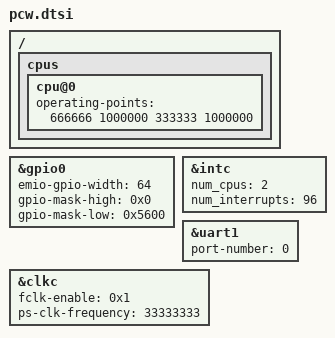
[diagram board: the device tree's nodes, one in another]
/*
 * CAUTION: This file is automatically generated by Xilinx.
 * Version:  
 * Today is: Thu Aug 22 16:15:34 2019
 */


/ {
	cpus {
		cpu@0 {
			operating-points = <666666 1000000 333333 1000000>;
		};
	};
};
&gpio0 {
	emio-gpio-width = <64>;
	gpio-mask-high = <0x0>;
	gpio-mask-low = <0x5600>;
};
&intc {
	num_cpus = <2>;
	num_interrupts = <96>;
};
&uart1 {
	device_type = "serial";
	port-number = <0>;
	status = "okay";
};
&clkc {
	fclk-enable = <0x1>;
	ps-clk-frequency = <33333333>;
};
